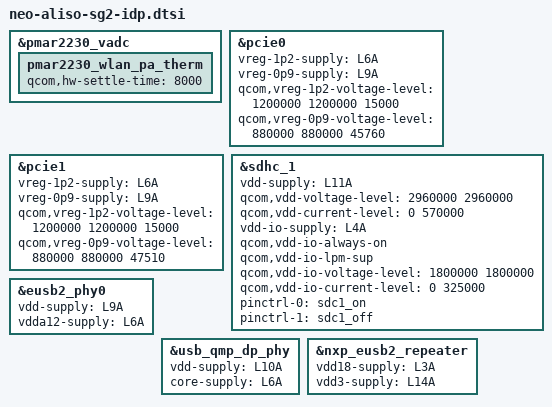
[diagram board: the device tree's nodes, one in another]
#include "neo-aliso-pmic-overlay.dtsi"

&pmar2230_vadc {
	pmar2230_wlan_pa_therm {
		qcom,hw-settle-time = <8000>;
	};
};

&pcie0 {
	vreg-1p2-supply = <&L6A>;
	vreg-0p9-supply = <&L9A>;

	qcom,vreg-1p2-voltage-level = <1200000 1200000 15000>;
	qcom,vreg-0p9-voltage-level = <880000 880000 45760>;
};

&pcie1 {
	vreg-1p2-supply = <&L6A>;
	vreg-0p9-supply = <&L9A>;

	qcom,vreg-1p2-voltage-level = <1200000 1200000 15000>;
	qcom,vreg-0p9-voltage-level = <880000 880000 47510>;
};

&sdhc_1 {
	status = "ok";

	vdd-supply = <&L11A>;
	qcom,vdd-voltage-level = <2960000 2960000>;
	qcom,vdd-current-level = <0 570000>;

	vdd-io-supply = <&L4A>;
	qcom,vdd-io-always-on;
	qcom,vdd-io-lpm-sup;
	qcom,vdd-io-voltage-level = <1800000 1800000>;
	qcom,vdd-io-current-level = <0 325000>;

	pinctrl-names = "default", "sleep";
	pinctrl-0 = <&sdc1_on>;
	pinctrl-1 = <&sdc1_off>;
};

&eusb2_phy0 {
	vdd-supply = <&L9A>;
	vdda12-supply = <&L6A>;
};

&usb_qmp_dp_phy {
	vdd-supply = <&L10A>;
	core-supply = <&L6A>;
};

&nxp_eusb2_repeater {
	vdd18-supply = <&L3A>;
	vdd3-supply = <&L14A>;
};
